VERSION "Excel 2 DBC"

NS_ :

BS_:

BU_: ControlUnit Seat

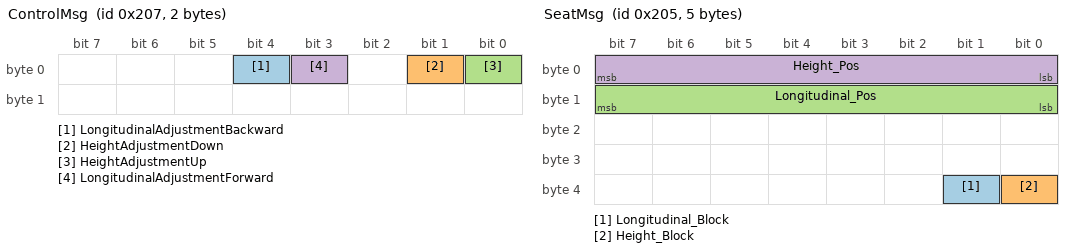
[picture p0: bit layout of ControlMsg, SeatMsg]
BO_ 519 ControlMsg: 2 ControlUnit
 SG_ LongitudinalAdjustmentBackward : 4|1@1+ (1,0) [0|1] "" Vector__XXX
 SG_ HeightAdjustmentDown : 1|1@1+ (1,0) [0|1] "" Vector__XXX
 SG_ HeightAdjustmentUp : 0|1@1+ (1,0) [0|1] "" Seat
 SG_ LongitudinalAdjustmentForward : 3|1@1+ (1,0) [0|1] "" Seat

BO_ 517 SeatMsg: 5 Seat
 SG_ Longitudinal_Block : 33|1@1+ (1,0) [0|1] "" ControlUnit
 SG_ Height_Block : 32|1@1+ (1,0) [0|1] "" ControlUnit
 SG_ Longitudinal_Pos : 8|8@1+ (1,0) [0|255] "" ControlUnit
 SG_ Height_Pos : 0|8@1+ (1,0) [0|255] "" ControlUnit
